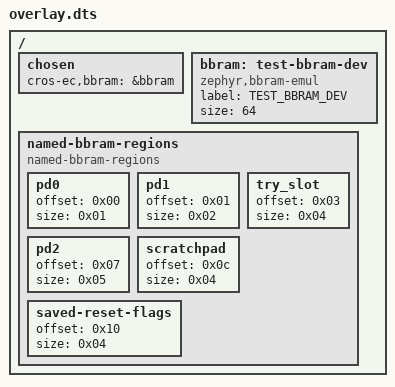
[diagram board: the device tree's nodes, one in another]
/* Copyright 2020 The Chromium OS Authors. All rights reserved.
 * Use of this source code is governed by a BSD-style license that can be
 * found in the LICENSE file.
 */

/ {
	chosen {
		cros-ec,bbram = &bbram;
	};

	bbram: test-bbram-dev {
		compatible = "zephyr,bbram-emul";
		label = "TEST_BBRAM_DEV";
		size = <64>;
	};

	named-bbram-regions {
		compatible = "named-bbram-regions";
		pd0 {
			offset = <0x00>;
			size = <0x01>;
		};
		pd1 {
			offset = <0x01>;
			size = <0x02>;
		};
		try_slot {
			offset = <0x03>;
			size = <0x04>;
		};
		pd2 {
			offset = <0x07>;
			size = <0x05>;
		};
		scratchpad {
			offset = <0x0c>;
			size = <0x04>;
		};
		saved-reset-flags {
			offset = <0x10>;
			size = <0x04>;
		};
	};
};
